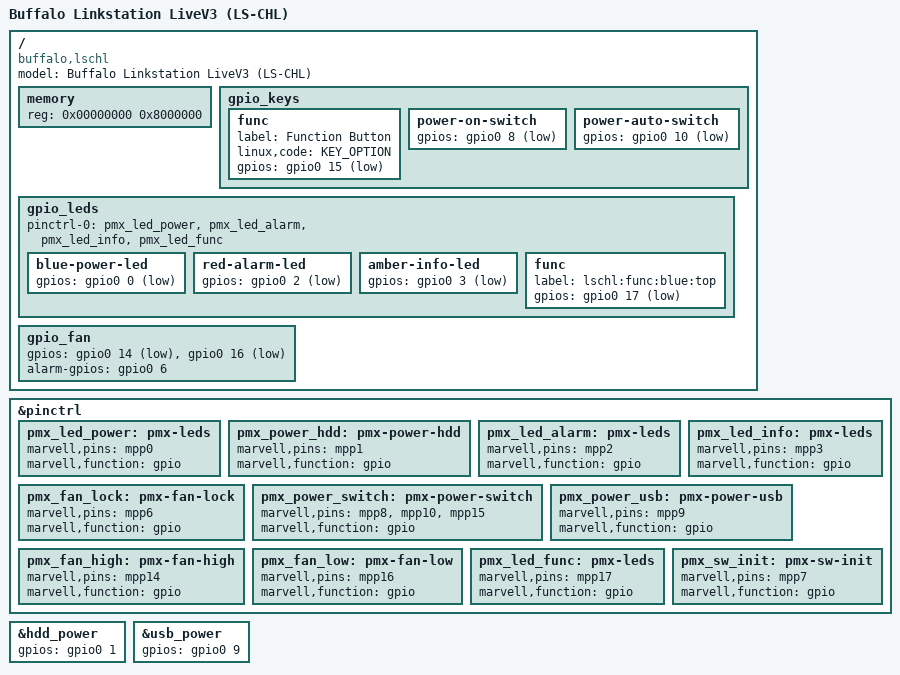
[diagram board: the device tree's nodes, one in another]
/dts-v1/;
#include "orion5x-linkstation.dtsi"
#include "mvebu-linkstation-gpio-simple.dtsi"
#include "mvebu-linkstation-fan.dtsi"
#include <dt-bindings/gpio/gpio.h>
/ {
	model = "Buffalo Linkstation LiveV3 (LS-CHL)";
	compatible = "buffalo,lschl", "marvell,orion5x-88f5182", "marvell,orion5x";
	memory {  
		device_type = "memory";
		reg = <0x00000000 0x8000000>;
	};
	gpio_keys {
		func {
			label = "Function Button";
			linux,code = <KEY_OPTION>;
			gpios = <&gpio0 15 GPIO_ACTIVE_LOW>;
		};
		power-on-switch {
			gpios = <&gpio0 8 GPIO_ACTIVE_LOW>;
		};
		power-auto-switch {
			gpios = <&gpio0 10 GPIO_ACTIVE_LOW>;
		};
	};
	gpio_leds {
		pinctrl-0 = <&pmx_led_power &pmx_led_alarm &pmx_led_info &pmx_led_func>;
		blue-power-led {
			gpios = <&gpio0 0 GPIO_ACTIVE_LOW>;
		};
		red-alarm-led {
			gpios = <&gpio0 2 GPIO_ACTIVE_LOW>;
		};
		amber-info-led {
			gpios = <&gpio0 3 GPIO_ACTIVE_LOW>;
		};
		func {
			label = "lschl:func:blue:top";
			gpios = <&gpio0 17 GPIO_ACTIVE_LOW>;
		};
	};
	gpio_fan {
		gpios = <&gpio0 14 GPIO_ACTIVE_LOW
			 &gpio0 16 GPIO_ACTIVE_LOW>;
		alarm-gpios = <&gpio0 6 GPIO_ACTIVE_HIGH>;
	};
};
&pinctrl {
	pmx_led_power: pmx-leds {
		marvell,pins = "mpp0";
		marvell,function = "gpio";
	};
	pmx_power_hdd: pmx-power-hdd {
		marvell,pins = "mpp1";
		marvell,function = "gpio";
	};
	pmx_led_alarm: pmx-leds {
		marvell,pins = "mpp2";
		marvell,function = "gpio";
	};
	pmx_led_info: pmx-leds {
		marvell,pins = "mpp3";
		marvell,function = "gpio";
	};
	pmx_fan_lock: pmx-fan-lock {
		marvell,pins = "mpp6";
		marvell,function = "gpio";
	};
	pmx_power_switch: pmx-power-switch {
		marvell,pins = "mpp8", "mpp10", "mpp15";
		marvell,function = "gpio";
	};
	pmx_power_usb: pmx-power-usb {
		marvell,pins = "mpp9";
		marvell,function = "gpio";
	};
	pmx_fan_high: pmx-fan-high {
		marvell,pins = "mpp14";
		marvell,function = "gpio";
	};
	pmx_fan_low: pmx-fan-low {
		marvell,pins = "mpp16";
		marvell,function = "gpio";
	};
	pmx_led_func: pmx-leds {
		marvell,pins = "mpp17";
		marvell,function = "gpio";
	};
	pmx_sw_init: pmx-sw-init {
		marvell,pins = "mpp7";
		marvell,function = "gpio";
	};
};
&hdd_power {
	gpios = <&gpio0 1 GPIO_ACTIVE_HIGH>;
};
&usb_power {
	gpios = <&gpio0 9 GPIO_ACTIVE_HIGH>;
};
